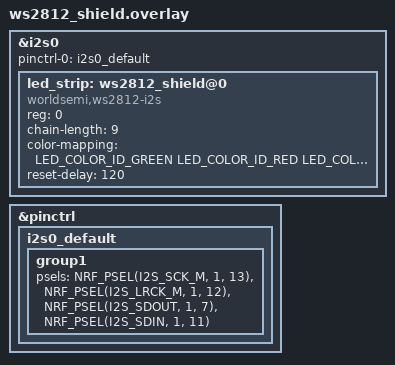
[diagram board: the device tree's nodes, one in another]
#include <zephyr/dt-bindings/led/led.h>

&i2s0 {
    status = "okay";
    pinctrl-0=<&i2s0_default>;
    pinctrl-names = "default";

    led_strip: ws2812_shield@0 {
        reg = <0>;
        compatible = "worldsemi,ws2812-i2s";
        status = "okay";
        chain-length = <9>;
        color-mapping = <LED_COLOR_ID_GREEN LED_COLOR_ID_RED LED_COLOR_ID_BLUE>;
        reset-delay = <120>;
    };
};

&pinctrl {
    i2s0_default: i2s0_default {
        group1 {
            psels = <NRF_PSEL(I2S_SCK_M, 1, 13)>,
                    <NRF_PSEL(I2S_LRCK_M, 1, 12)>,
                    <NRF_PSEL(I2S_SDOUT, 1, 7)>,
                    <NRF_PSEL(I2S_SDIN, 1, 11)>;
        };
    };
};
